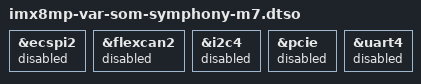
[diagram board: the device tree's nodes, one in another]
// SPDX-License-Identifier: (GPL-2.0+ OR MIT)
/*
 * Cortex-M7 support for Variscite VAR-SOM-MX8M-PLUS on Symphony-Board
 *
 * Link: https://variscite.com/carrier-boards/symphony-board/
 *
 * Copyright (C) 2026 Variscite Ltd. - https://www.variscite.com/
 *
 */

/dts-v1/;
/plugin/;

#include "imx8mp-var-common-m7.dtsi"

/* Reserve the peripherals used by the Cortex-M7 firmware. */
&ecspi2 {
	status = "reserved";
};

&flexcan2 {
	status = "reserved";
};

&i2c4 {
	status = "reserved";
};

/* The PCIe reset GPIO is provided by the expander on I2C4. */
&pcie {
	status = "disabled";
};

&uart4 {
	status = "reserved";
};
